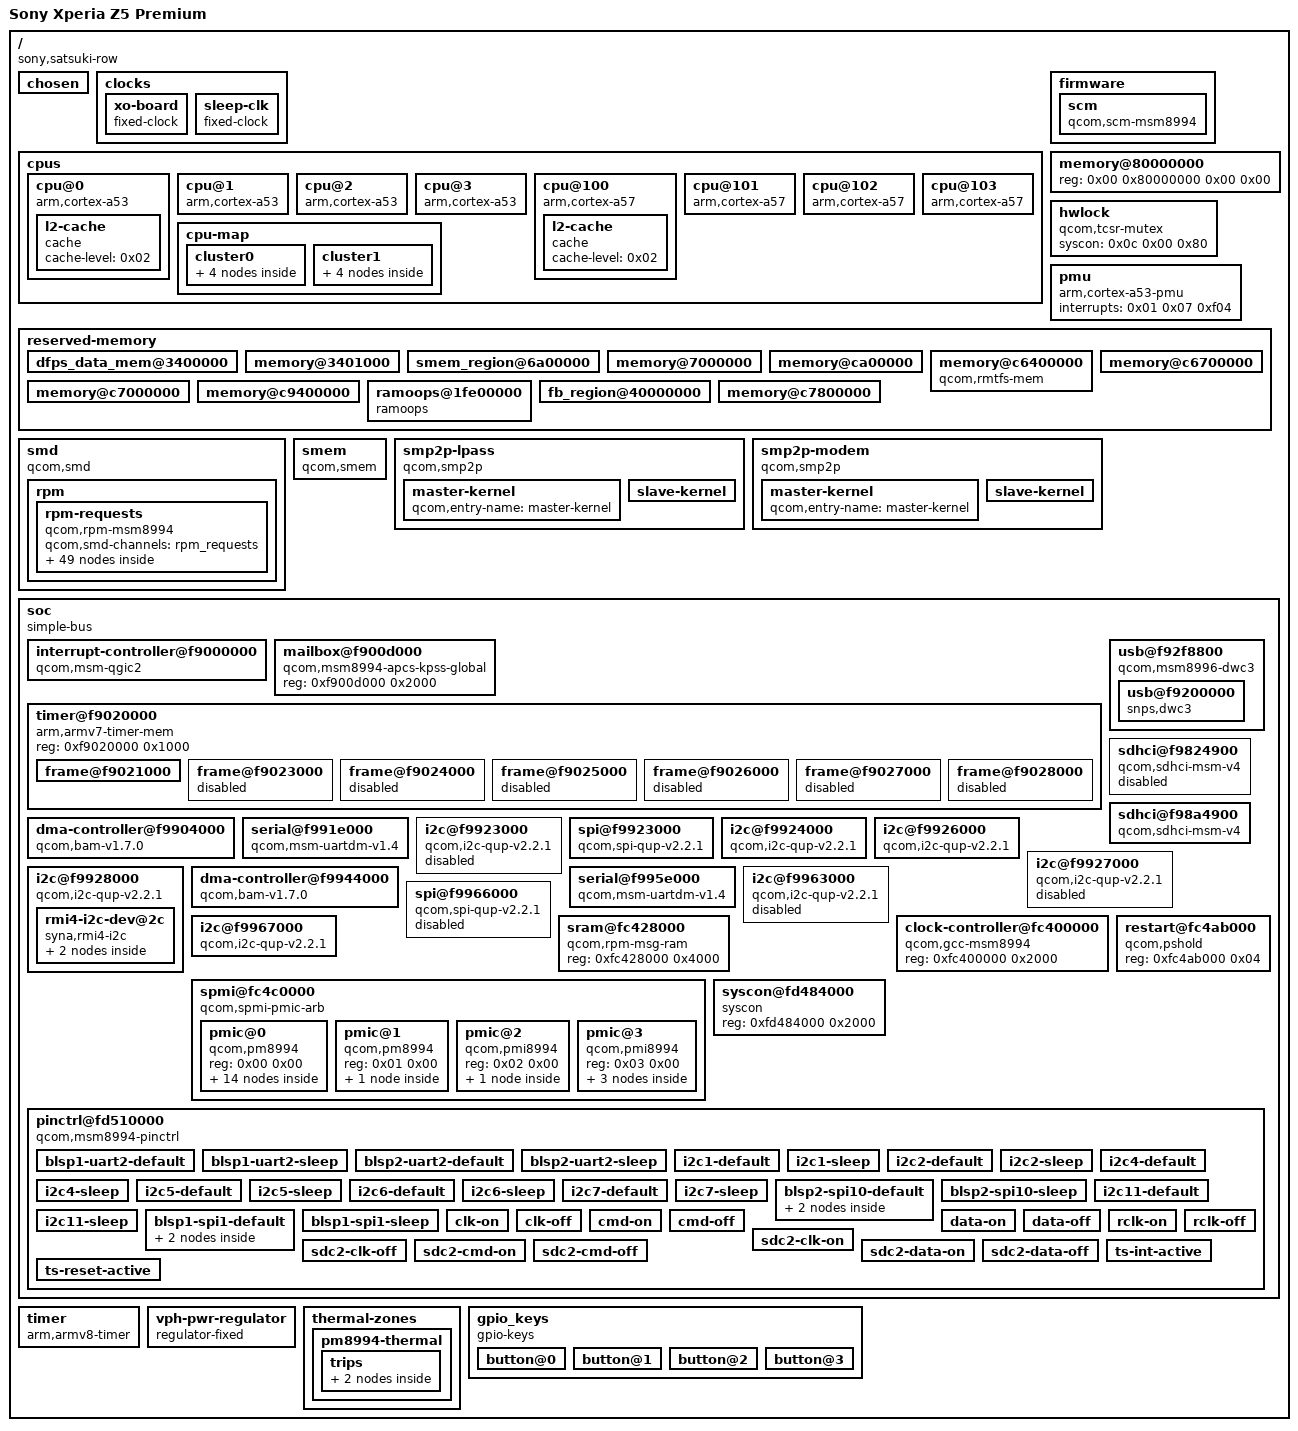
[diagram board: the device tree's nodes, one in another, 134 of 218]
/dts-v1/;

/ {
	interrupt-parent = <0x01>;
	#address-cells = <0x02>;
	#size-cells = <0x02>;
	qcom,msm-id = <0xcf 0x20000 0xcf 0x20001>;
	qcom,pmic-id = <0x10009 0x1000a 0x00 0x00>;
	qcom,board-id = <0x08 0x00>;
	model = "Sony Xperia Z5 Premium";
	compatible = "sony,satsuki-row\0qcom,msm8994";

	chosen {
	};

	clocks {

		xo-board {
			compatible = "fixed-clock";
			#clock-cells = <0x00>;
			clock-frequency = <0x124f800>;
			clock-output-names = "xo_board";
			phandle = <0x19>;
		};

		sleep-clk {
			compatible = "fixed-clock";
			#clock-cells = <0x00>;
			clock-frequency = <0x8000>;
			clock-output-names = "sleep_clk";
			phandle = <0x4a>;
		};
	};

	cpus {
		#address-cells = <0x02>;
		#size-cells = <0x00>;

		cpu@0 {
			device_type = "cpu";
			compatible = "arm,cortex-a53";
			reg = <0x00 0x00>;
			enable-method = "psci";
			next-level-cache = <0x02>;
			phandle = <0x04>;

			l2-cache {
				compatible = "cache";
				cache-level = <0x02>;
				phandle = <0x02>;
			};
		};

		cpu@1 {
			device_type = "cpu";
			compatible = "arm,cortex-a53";
			reg = <0x00 0x01>;
			enable-method = "psci";
			next-level-cache = <0x02>;
			phandle = <0x05>;
		};

		cpu@2 {
			device_type = "cpu";
			compatible = "arm,cortex-a53";
			reg = <0x00 0x02>;
			enable-method = "psci";
			next-level-cache = <0x02>;
			phandle = <0x06>;
		};

		cpu@3 {
			device_type = "cpu";
			compatible = "arm,cortex-a53";
			reg = <0x00 0x03>;
			enable-method = "psci";
			next-level-cache = <0x02>;
			phandle = <0x07>;
		};

		cpu@100 {
			device_type = "cpu";
			compatible = "arm,cortex-a57";
			reg = <0x00 0x100>;
			enable-method = "psci";
			next-level-cache = <0x03>;
			phandle = <0x08>;

			l2-cache {
				compatible = "cache";
				cache-level = <0x02>;
				phandle = <0x03>;
			};
		};

		cpu@101 {
			device_type = "cpu";
			compatible = "arm,cortex-a57";
			reg = <0x00 0x101>;
			enable-method = "psci";
			next-level-cache = <0x03>;
			phandle = <0x09>;
		};

		cpu@102 {
			device_type = "cpu";
			compatible = "arm,cortex-a57";
			reg = <0x00 0x102>;
			enable-method = "psci";
			next-level-cache = <0x03>;
			phandle = <0x0a>;
		};

		cpu@103 {
			device_type = "cpu";
			compatible = "arm,cortex-a57";
			reg = <0x00 0x103>;
			enable-method = "psci";
			next-level-cache = <0x03>;
			phandle = <0x0b>;
		};

		cpu-map {

			cluster0 {

				core0 {
					cpu = <0x04>;
				};

				core1 {
					cpu = <0x05>;
				};

				core2 {
					cpu = <0x06>;
				};

				core3 {
					cpu = <0x07>;
				};
			};

			cluster1 {

				core0 {
					cpu = <0x08>;
				};

				core1 {
					cpu = <0x09>;
				};

				core2 {
					cpu = <0x0a>;
					phandle = <0x4b>;
				};

				core3 {
					cpu = <0x0b>;
					phandle = <0x4c>;
				};
			};
		};
	};

	firmware {

		scm {
			compatible = "qcom,scm-msm8994\0qcom,scm";
		};
	};

	memory@80000000 {
		device_type = "memory";
		reg = <0x00 0x80000000 0x00 0x00>;
	};

	hwlock {
		compatible = "qcom,tcsr-mutex";
		syscon = <0x0c 0x00 0x80>;
		#hwlock-cells = <0x01>;
		phandle = <0x17>;
	};

	pmu {
		compatible = "arm,cortex-a53-pmu";
		interrupts = <0x01 0x07 0xf04>;
	};

	reserved-memory {
		#address-cells = <0x02>;
		#size-cells = <0x02>;
		ranges;

		dfps_data_mem@3400000 {
			reg = <0x00 0x3400000 0x00 0x1000>;
			no-map;
			phandle = <0x4d>;
		};

		memory@3401000 {
			reg = <0x00 0x3401000 0x00 0x2200000>;
			no-map;
			phandle = <0x4e>;
		};

		smem_region@6a00000 {
			reg = <0x00 0x6a00000 0x00 0x200000>;
			no-map;
			phandle = <0x15>;
		};

		memory@7000000 {
			reg = <0x00 0x7000000 0x00 0x5a00000>;
			no-map;
			phandle = <0x4f>;
		};

		memory@ca00000 {
			reg = <0x00 0xca00000 0x00 0x1f00000>;
			no-map;
			phandle = <0x50>;
		};

		memory@c6400000 {
			compatible = "qcom,rmtfs-mem";
			reg = <0x00 0xc6400000 0x00 0x180000>;
			no-map;
			qcom,client-id = <0x01>;
			phandle = <0x51>;
		};

		memory@c6700000 {
			reg = <0x00 0xc6700000 0x00 0x100000>;
			no-map;
			phandle = <0x52>;
		};

		memory@c7000000 {
			reg = <0x00 0xc7000000 0x00 0x800000>;
			no-map;
			phandle = <0x53>;
		};

		memory@c9400000 {
			reg = <0x00 0xc9400000 0x00 0x3f00000>;
			no-map;
			phandle = <0x54>;
		};

		ramoops@1fe00000 {
			compatible = "ramoops";
			reg = <0x00 0x1fe00000 0x00 0x200000>;
			console-size = <0x100000>;
			record-size = <0x10000>;
			ftrace-size = <0x10000>;
			pmsg-size = <0x80000>;
		};

		fb_region@40000000 {
			reg = <0x00 0x40000000 0x00 0x1000000>;
			no-map;
			phandle = <0x55>;
		};

		memory@c7800000 {
			reg = <0x00 0xc7800000 0x00 0x1900000>;
			no-map;
			phandle = <0x56>;
		};
	};

	smd {
		compatible = "qcom,smd";

		rpm {
			interrupts = <0x00 0xa8 0x01>;
			qcom,ipc = <0x0d 0x08 0x00>;
			qcom,smd-edge = <0x0f>;
			qcom,local-pid = <0x00>;
			qcom,remote-pid = <0x06>;

			rpm-requests {
				compatible = "qcom,rpm-msm8994";
				qcom,smd-channels = "rpm_requests";
				phandle = <0x57>;

				rpmcc {
					compatible = "qcom,rpmcc-msm8994";
					#clock-cells = <0x01>;
					phandle = <0x58>;
				};

				power-controller {
					compatible = "qcom,msm8994-rpmpd";
					#power-domain-cells = <0x01>;
					operating-points-v2 = <0x0e>;
					phandle = <0x59>;

					opp-table {
						compatible = "operating-points-v2";
						phandle = <0x0e>;

						opp1 {
							opp-level = <0x01>;
							phandle = <0x5a>;
						};

						opp2 {
							opp-level = <0x02>;
							phandle = <0x5b>;
						};

						opp3 {
							opp-level = <0x03>;
							phandle = <0x5c>;
						};

						opp4 {
							opp-level = <0x04>;
							phandle = <0x5d>;
						};

						opp5 {
							opp-level = <0x05>;
							phandle = <0x5e>;
						};

						opp6 {
							opp-level = <0x06>;
							phandle = <0x5f>;
						};
					};
				};

				pm8994-regulators {
					compatible = "qcom,rpm-pm8994-regulators";
					vdd_s1-supply = <0x0f>;
					vdd_s2-supply = <0x0f>;
					vdd_s3-supply = <0x0f>;
					vdd_s4-supply = <0x0f>;
					vdd_s5-supply = <0x0f>;
					vdd_s6-supply = <0x0f>;
					vdd_s7-supply = <0x0f>;
					vdd_s8-supply = <0x0f>;
					vdd_s9-supply = <0x0f>;
					vdd_s10-supply = <0x0f>;
					vdd_s11-supply = <0x0f>;
					vdd_s12-supply = <0x0f>;
					vdd_l1-supply = <0x10>;
					vdd_l2_l26_l28-supply = <0x11>;
					vdd_l3_l11-supply = <0x11>;
					vdd_l4_l27_l31-supply = <0x11>;
					vdd_l5_l7-supply = <0x12>;
					vdd_l6_l12_l32-supply = <0x12>;
					vdd_l8_l16_l30-supply = <0x0f>;
					vdd_l9_l10_l18_l22-supply = <0x13>;
					vdd_l13_l19_l23_l24-supply = <0x13>;
					vdd_l14_l15-supply = <0x12>;
					vdd_l17_l29-supply = <0x13>;
					vdd_l20_l21-supply = <0x13>;
					vdd_l25-supply = <0x11>;
					vdd_lvs1_lvs2-supply = <0x14>;
					phandle = <0x60>;

					s3 {
						regulator-min-microvolt = <0x13d620>;
						regulator-max-microvolt = <0x13d620>;
						phandle = <0x11>;
					};

					s4 {
						regulator-min-microvolt = <0x1b7740>;
						regulator-max-microvolt = <0x1b7740>;
						regulator-allow-set-load;
						regulator-always-on;
						regulator-system-load = <0x4f588>;
						phandle = <0x14>;
					};

					s5 {
						regulator-min-microvolt = <0x20ce70>;
						regulator-max-microvolt = <0x20ce70>;
						phandle = <0x12>;
					};

					s7 {
						regulator-min-microvolt = <0xf4240>;
						regulator-max-microvolt = <0xf4240>;
						phandle = <0x61>;
					};

					l1 {
						regulator-min-microvolt = <0xf4240>;
						regulator-max-microvolt = <0xf4240>;
						phandle = <0x62>;
					};

					l2 {
						regulator-min-microvolt = <0x1312d0>;
						regulator-max-microvolt = <0x1312d0>;
						regulator-allow-set-load;
						regulator-system-load = <0x2710>;
						phandle = <0x63>;
					};

					l3 {
						regulator-min-microvolt = <0x10c8e0>;
						regulator-max-microvolt = <0x10c8e0>;
						phandle = <0x64>;
					};

					l4 {
						regulator-min-microvolt = <0x12b128>;
						regulator-max-microvolt = <0x12b128>;
						phandle = <0x65>;
					};

					l6 {
						regulator-min-microvolt = <0x1b7740>;
						regulator-max-microvolt = <0x1b7740>;
						phandle = <0x66>;
					};

					l8 {
						regulator-min-microvolt = <0x1b7740>;
						regulator-max-microvolt = <0x1b7740>;
						phandle = <0x67>;
					};

					l9 {
						regulator-min-microvolt = <0x1b7740>;
						regulator-max-microvolt = <0x1b7740>;
						phandle = <0x68>;
					};

					l10 {
						regulator-min-microvolt = <0x1b7740>;
						regulator-max-microvolt = <0x1b7740>;
						phandle = <0x69>;
					};

					l11 {
						regulator-min-microvolt = <0x124f80>;
						regulator-max-microvolt = <0x124f80>;
						phandle = <0x6a>;
					};

					l12 {
						regulator-min-microvolt = <0x1b7740>;
						regulator-max-microvolt = <0x1b7740>;
						regulator-allow-set-load;
						regulator-system-load = <0x2710>;
						phandle = <0x6b>;
					};

					l13 {
						regulator-min-microvolt = <0x1b7740>;
						regulator-max-microvolt = <0x2d0370>;
						phandle = <0x2a>;
					};

					l14 {
						regulator-min-microvolt = <0x1c3a90>;
						regulator-max-microvolt = <0x1c3a90>;
						regulator-allow-set-load;
						regulator-system-load = <0x2710>;
						phandle = <0x6c>;
					};

					l15 {
						regulator-min-microvolt = <0x1b7740>;
						regulator-max-microvolt = <0x1b7740>;
						phandle = <0x6d>;
					};

					l16 {
						regulator-min-microvolt = <0x2932e0>;
						regulator-max-microvolt = <0x2932e0>;
						phandle = <0x6e>;
					};

					l17 {
						regulator-min-microvolt = <0x2191c0>;
						regulator-max-microvolt = <0x2191c0>;
						phandle = <0x6f>;
					};

					l18 {
						regulator-min-microvolt = <0x2b7cd0>;
						regulator-max-microvolt = <0x2b7cd0>;
						regulator-always-on;
						phandle = <0x70>;
					};

					l19 {
						regulator-min-microvolt = <0x2b7cd0>;
						regulator-max-microvolt = <0x2b7cd0>;
						phandle = <0x71>;
					};

					l20 {
						regulator-min-microvolt = <0x2d0370>;
						regulator-max-microvolt = <0x2d0370>;
						regulator-always-on;
						regulator-boot-on;
						regulator-allow-set-load;
						regulator-system-load = <0x8b290>;
						phandle = <0x72>;
					};

					l21 {
						regulator-min-microvolt = <0x2d0370>;
						regulator-max-microvolt = <0x2d0370>;
						regulator-always-on;
						regulator-allow-set-load;
						regulator-system-load = "\0\f5";
						phandle = <0x29>;
					};

					l22 {
						regulator-min-microvolt = <0x2dc6c0>;
						regulator-max-microvolt = <0x2dc6c0>;
						phandle = <0x3d>;
					};

					l23 {
						regulator-min-microvolt = <0x2ab980>;
						regulator-max-microvolt = <0x2ab980>;
						phandle = <0x73>;
					};

					l24 {
						regulator-min-microvolt = <0x2eebb8>;
						regulator-max-microvolt = <0x3010b0>;
						phandle = <0x74>;
					};

					l25 {
						regulator-min-microvolt = <0xf4240>;
						regulator-max-microvolt = <0xf4240>;
						phandle = <0x75>;
					};

					l26 {
						regulator-min-microvolt = <0xf116c>;
						regulator-max-microvolt = <0xf116c>;
						phandle = <0x76>;
					};

					l27 {
						regulator-min-microvolt = <0x124f80>;
						regulator-max-microvolt = <0x124f80>;
						phandle = <0x77>;
					};

					l28 {
						regulator-min-microvolt = <0xf4240>;
						regulator-max-microvolt = <0xf4240>;
						regulator-allow-set-load;
						regulator-system-load = <0x2710>;
						phandle = <0x78>;
					};

					l29 {
						regulator-min-microvolt = <0x2932e0>;
						regulator-max-microvolt = <0x2932e0>;
						phandle = <0x79>;
					};

					l30 {
						regulator-min-microvolt = <0x1b7740>;
						regulator-max-microvolt = <0x1b7740>;
						phandle = <0x7a>;
					};

					l31 {
						regulator-min-microvolt = <0x124f80>;
						regulator-max-microvolt = <0x124f80>;
						regulator-allow-set-load;
						regulator-system-load = <0x2710>;
						phandle = <0x7b>;
					};

					l32 {
						regulator-min-microvolt = <0x1b7740>;
						regulator-max-microvolt = <0x1b7740>;
						phandle = <0x7c>;
					};

					lvs1 {
						phandle = <0x7d>;
					};

					lvs2 {
						phandle = <0x7e>;
					};
				};

				pmi8994-regulators {
					compatible = "qcom,rpm-pmi8994-regulators";
					vdd_s1-supply = <0x0f>;
					vdd_bst_byp-supply = <0x0f>;
					phandle = <0x7f>;

					s1 {
						regulator-min-microvolt = <0xfa3e8>;
						regulator-max-microvolt = <0xfa3e8>;
						phandle = <0x10>;
					};

					boost-bypass {
						regulator-min-microvolt = <0x3010b0>;
						regulator-max-microvolt = <0x36ee80>;
						phandle = <0x13>;
					};
				};
			};
		};
	};

	smem {
		compatible = "qcom,smem";
		memory-region = <0x15>;
		qcom,rpm-msg-ram = <0x16>;
		hwlocks = <0x17 0x03>;
	};

	smp2p-lpass {
		compatible = "qcom,smp2p";
		qcom,smem = <0x1bb 0x1ad>;
		interrupts = <0x00 0x9e 0x01>;
		qcom,ipc = <0x0d 0x08 0x0a>;
		qcom,local-pid = <0x00>;
		qcom,remote-pid = <0x02>;

		master-kernel {
			qcom,entry-name = "master-kernel";
			#qcom,smem-state-cells = <0x01>;
			phandle = <0x80>;
		};

		slave-kernel {
			qcom,entry-name = "slave-kernel";
			interrupt-controller;
			#interrupt-cells = <0x02>;
			phandle = <0x81>;
		};
	};

	smp2p-modem {
		compatible = "qcom,smp2p";
		qcom,smem = <0x1b3 0x1ac>;
		interrupt-parent = <0x01>;
		interrupts = <0x00 0x1b 0x01>;
		qcom,ipc = <0x0d 0x08 0x0e>;
		qcom,local-pid = <0x00>;
		qcom,remote-pid = <0x01>;

		master-kernel {
			qcom,entry-name = "master-kernel";
			#qcom,smem-state-cells = <0x01>;
			phandle = <0x82>;
		};

		slave-kernel {
			qcom,entry-name = "slave-kernel";
			interrupt-controller;
			#interrupt-cells = <0x02>;
			phandle = <0x83>;
		};
	};

	soc {
		#address-cells = <0x01>;
		#size-cells = <0x01>;
		ranges = <0x00 0x00 0x00 0xffffffff>;
		compatible = "simple-bus";
		phandle = <0x84>;

		interrupt-controller@f9000000 {
			compatible = "qcom,msm-qgic2";
			interrupt-controller;
			#interrupt-cells = <0x03>;
			reg = <0xf9000000 0x1000 0xf9002000 0x1000>;
			phandle = <0x01>;
		};

		mailbox@f900d000 {
			compatible = "qcom,msm8994-apcs-kpss-global\0syscon";
			reg = <0xf900d000 0x2000>;
			#mbox-cells = <0x01>;
			phandle = <0x0d>;
		};

		timer@f9020000 {
			#address-cells = <0x01>;
			#size-cells = <0x01>;
			ranges;
			compatible = "arm,armv7-timer-mem";
			reg = <0xf9020000 0x1000>;

			frame@f9021000 {
				frame-number = <0x00>;
				interrupts = <0x00 0x09 0x04 0x00 0x08 0x04>;
				reg = <0xf9021000 0x1000 0xf9022000 0x1000>;
			};

			frame@f9023000 {
				frame-number = <0x01>;
				interrupts = <0x00 0x0a 0x04>;
				reg = <0xf9023000 0x1000>;
				status = "disabled";
			};

			frame@f9024000 {
				frame-number = <0x02>;
				interrupts = <0x00 0x0b 0x04>;
				reg = <0xf9024000 0x1000>;
				status = "disabled";
			};

			frame@f9025000 {
				frame-number = <0x03>;
				interrupts = <0x00 0x0c 0x04>;
				reg = <0xf9025000 0x1000>;
				status = "disabled";
			};

			frame@f9026000 {
				frame-number = <0x04>;
				interrupts = <0x00 0x0d 0x04>;
				reg = <0xf9026000 0x1000>;
				status = "disabled";
			};

			frame@f9027000 {
				frame-number = <0x05>;
				interrupts = <0x00 0x0e 0x04>;
				reg = <0xf9027000 0x1000>;
				status = "disabled";
			};

			frame@f9028000 {
				frame-number = <0x06>;
				interrupts = <0x00 0x0f 0x04>;
				reg = <0xf9028000 0x1000>;
				status = "disabled";
			};
		};

		usb@f92f8800 {
			compatible = "qcom,msm8996-dwc3\0qcom,dwc3";
			reg = <0xf92f8800 0x400>;
			#address-cells = <0x01>;
			#size-cells = <0x01>;
			ranges;
			clocks = <0x18 0x72 0x18 0x6d 0x18 0x8a 0x18 0x73>;
			clock-names = "core\0iface\0sleep\0mock_utmi\0ref\0xo";
			assigned-clocks = <0x18 0x73 0x18 0x72>;
			assigned-clock-rates = <0x124f800 0x7270e00>;
			power-domains = <0x18 0x03>;
			qcom,select-utmi-as-pipe-clk;
			phandle = <0x85>;

			usb@f9200000 {
				compatible = "snps,dwc3";
				reg = <0xf9200000 0xcc00>;
				interrupts = <0x00 0x83 0x04>;
				snps,dis_u2_susphy_quirk;
				snps,dis_enblslpm_quirk;
				maximum-speed = "high-speed";
				dr_mode = "peripheral";
			};
		};

		sdhci@f9824900 {
			compatible = "qcom,sdhci-msm-v4";
			reg = <0xf9824900 0x1a0 0xf9824000 0x800>;
			reg-names = "hc_mem\0core_mem";
			interrupts = <0x00 0x7b 0x04 0x00 0x8a 0x04>;
			interrupt-names = "hc_irq\0pwr_irq";
			clocks = <0x18 0x68 0x18 0x76 0x19>;
			clock-names = "core\0iface\0xo";
			pinctrl-names = "default\0sleep";
			pinctrl-0 = <0x1a 0x1b 0x1c 0x1d>;
			pinctrl-1 = <0x1e 0x1f 0x20 0x21>;
			bus-width = <0x08>;
			non-removable;
			status = "disabled";
			phandle = <0x86>;
		};

		sdhci@f98a4900 {
			compatible = "qcom,sdhci-msm-v4";
			reg = <0xf98a4900 0x11c 0xf98a4000 0x800>;
			reg-names = "hc_mem\0core_mem";
			interrupts = <0x00 0x7d 0x04 0x00 0xdd 0x04>;
			interrupt-names = "hc_irq\0pwr_irq";
			clocks = <0x18 0x69 0x18 0x80 0x19>;
			clock-names = "core\0iface\0xo";
			pinctrl-names = "default\0sleep";
			pinctrl-0 = <0x22 0x23 0x24>;
			pinctrl-1 = <0x25 0x26 0x27>;
			cd-gpios = <0x28 0x64 0x00>;
			bus-width = <0x04>;
			status = "okay";
			vmmc-supply = <0x29>;
			vqmmc-supply = <0x2a>;
			phandle = <0x87>;
		};

		dma-controller@f9904000 {
			compatible = "qcom,bam-v1.7.0";
			reg = <0xf9904000 0x19000>;
			interrupts = <0x00 0xee 0x04>;
			clocks = <0x18 0x3a>;
			clock-names = "bam_clk";
			#dma-cells = <0x01>;
			qcom,ee = <0x00>;
			qcom,controlled-remotely;
			num-channels = <0x18>;
			qcom,num-ees = <0x04>;
			phandle = <0x2d>;
		};

		serial@f991e000 {
			compatible = "qcom,msm-uartdm-v1.4\0qcom,msm-uartdm";
			reg = <0xf991e000 0x1000>;
			interrupts = <0x00 0x6c 0x04>;
			clock-names = "core\0iface";
			clocks = <0x18 0x48 0x18 0x3a>;
			pinctrl-names = "default\0sleep";
			pinctrl-0 = <0x2b>;
			pinctrl-1 = <0x2c>;
			status = "okay";
			phandle = <0x88>;
		};

		i2c@f9923000 {
			compatible = "qcom,i2c-qup-v2.2.1";
			reg = <0xf9923000 0x500>;
			interrupts = <0x00 0x5f 0x04>;
			clocks = <0x18 0x3a 0x18 0x3b>;
			clock-names = "iface\0core";
			clock-frequency = <0x61a80>;
			dmas = <0x2d 0x0c 0x2d 0x0d>;
			dma-names = "tx\0rx";
			pinctrl-names = "default\0sleep";
			pinctrl-0 = <0x2e>;
			pinctrl-1 = <0x2f>;
			#address-cells = <0x01>;
			#size-cells = <0x00>;
			status = "disabled";
			phandle = <0x89>;
		};

		spi@f9923000 {
			compatible = "qcom,spi-qup-v2.2.1";
			reg = <0xf9923000 0x500>;
			interrupts = <0x00 0x5f 0x04>;
			clocks = <0x18 0x3c 0x18 0x3a>;
			clock-names = "core\0iface";
			spi-max-frequency = <0x124f800>;
			dmas = <0x2d 0x0c 0x2d 0x0d>;
			dma-names = "tx\0rx";
			pinctrl-names = "default\0sleep";
			pinctrl-0 = <0x30>;
			pinctrl-1 = <0x31>;
			#address-cells = <0x01>;
			#size-cells = <0x00>;
			status = "okay";
			phandle = <0x8a>;
		};

		i2c@f9924000 {
			compatible = "qcom,i2c-qup-v2.2.1";
			reg = <0xf9924000 0x500>;
			interrupts = <0x00 0x60 0x04>;
			clocks = <0x18 0x3a 0x18 0x3d>;
			clock-names = "iface\0core";
			clock-frequency = <0x56ab8>;
			dmas = <0x2d 0x0e 0x2d 0x0f>;
			dma-names = "tx\0rx";
			pinctrl-names = "default\0sleep";
			pinctrl-0 = <0x32>;
			pinctrl-1 = <0x33>;
			#address-cells = <0x01>;
			#size-cells = <0x00>;
			status = "okay";
			phandle = <0x8b>;
		};

		i2c@f9926000 {
			compatible = "qcom,i2c-qup-v2.2.1";
			reg = <0xf9926000 0x500>;
			interrupts = <0x00 0x62 0x04>;
			clocks = <0x18 0x3a 0x18 0x41>;
			clock-names = "iface\0core";
			clock-frequency = <0x56ab8>;
			dmas = <0x2d 0x12 0x2d 0x13>;
			dma-names = "tx\0rx";
			pinctrl-names = "default\0sleep";
			pinctrl-0 = <0x34>;
			pinctrl-1 = <0x35>;
			#address-cells = <0x01>;
			#size-cells = <0x00>;
			status = "okay";
			phandle = <0x8c>;
		};

		i2c@f9927000 {
			compatible = "qcom,i2c-qup-v2.2.1";
			reg = <0xf9927000 0x500>;
			interrupts = <0x00 0x63 0x04>;
			clocks = <0x18 0x3a 0x18 0x43>;
			clock-names = "iface\0core";
			clock-frequency = <0x61a80>;
			dmas = <0x36 0x14 0x36 0x15>;
			dma-names = "tx\0rx";
			pinctrl-names = "default\0sleep";
			pinctrl-0 = <0x37>;
			pinctrl-1 = <0x38>;
			#address-cells = <0x01>;
			#size-cells = <0x00>;
			status = "disabled";
			phandle = <0x8d>;
		};

		i2c@f9928000 {
			compatible = "qcom,i2c-qup-v2.2.1";
			reg = <0xf9928000 0x500>;
			interrupts = <0x00 0x64 0x04>;
			clocks = <0x18 0x3a 0x18 0x45>;
			clock-names = "iface\0core";
			clock-frequency = <0x56ab8>;
			dmas = <0x2d 0x16 0x2d 0x17>;
			dma-names = "tx\0rx";
			pinctrl-names = "default\0sleep";
			pinctrl-0 = <0x39>;
			pinctrl-1 = <0x3a>;
			#address-cells = <0x01>;
			#size-cells = <0x00>;
			status = "okay";
			phandle = <0x8e>;

			rmi4-i2c-dev@2c {
				compatible = "syna,rmi4-i2c";
				reg = <0x2c>;
				#address-cells = <0x01>;
				#size-cells = <0x00>;
				interrupt-parent = <0x28>;
				interrupts = <0x2a 0x02>;
				pinctrl-names = "default";
				pinctrl-0 = <0x3b 0x3c>;
				vdd-supply = <0x3d>;
				vio-supply = <0x14>;
				syna,reset-delay-ms = <0xdc>;
				syna,startup-delay-ms = <0xdc>;
				phandle = <0x8f>;

				rmi4-f01@1 {
					reg = <0x01>;
					syna,nosleep-mode = <0x01>;
				};

				rmi4-f11@11 {
					reg = <0x11>;
					syna,sensor-type = <0x01>;
				};
			};
		};

		dma-controller@f9944000 {
			compatible = "qcom,bam-v1.7.0";
			reg = <0xf9944000 0x19000>;
			interrupts = <0x00 0xef 0x04>;
			clocks = <0x18 0x4d>;
			clock-names = "bam_clk";
			#dma-cells = <0x01>;
			qcom,ee = <0x00>;
			qcom,controlled-remotely;
			num-channels = <0x18>;
			qcom,num-ees = <0x04>;
			phandle = <0x36>;
		};

		serial@f995e000 {
			compatible = "qcom,msm-uartdm-v1.4\0qcom,msm-uartdm";
			reg = <0xf995e000 0x1000>;
			interrupts = <0x00 0x72 0x04>;
			clock-names = "core\0iface";
			clocks = <0x18 0x5b 0x18 0x4d>;
			dmas = <0x36 0x02 0x36 0x03>;
			dma-names = "tx\0rx";
			pinctrl-names = "default\0sleep";
			pinctrl-0 = <0x3e>;
			pinctrl-1 = <0x3f>;
			status = "okay";
			phandle = <0x90>;
		};

		i2c@f9963000 {
			compatible = "qcom,i2c-qup-v2.2.1";
			reg = <0xf9963000 0x500>;
			interrupts = <0x00 0x65 0x04>;
			clocks = <0x18 0x4d 0x18 0x4e>;
			clock-names = "iface\0core";
			clock-frequency = <0x61a80>;
			dmas = <0x36 0x0c 0x36 0x0d>;
			dma-names = "tx\0rx";
			pinctrl-names = "default\0sleep";
			pinctrl-0 = <0x40>;
			pinctrl-1 = <0x41>;
			#address-cells = <0x01>;
			#size-cells = <0x00>;
			status = "disabled";
			phandle = <0x91>;
		};

		spi@f9966000 {
			compatible = "qcom,spi-qup-v2.2.1";
			reg = <0xf9966000 0x500>;
			interrupts = <0x00 0x68 0x04>;
			clocks = <0x18 0x55 0x18 0x4d>;
			clock-names = "core\0iface";
			spi-max-frequency = <0x124f800>;
			dmas = <0x36 0x12 0x36 0x13>;
			dma-names = "tx\0rx";
			pinctrl-names = "default\0sleep";
			pinctrl-0 = <0x42>;
			pinctrl-1 = <0x43>;
			#address-cells = <0x01>;
			#size-cells = <0x00>;
			status = "disabled";
			phandle = <0x92>;
		};

		i2c@f9967000 {
			compatible = "qcom,i2c-qup-v2.2.1";
			reg = <0xf9967000 0x500>;
			interrupts = <0x00 0x69 0x04>;
			clocks = <0x18 0x4d 0x18 0x56>;
			clock-names = "iface\0core";
			clock-frequency = <0x56ab8>;
			dmas = <0x36 0x14 0x36 0x15>;
			dma-names = "tx\0rx";
			pinctrl-names = "default\0sleep";
			pinctrl-0 = <0x44>;
			pinctrl-1 = <0x45>;
			#address-cells = <0x01>;
			#size-cells = <0x00>;
			status = "okay";
			phandle = <0x93>;
		};

		clock-controller@fc400000 {
			compatible = "qcom,gcc-msm8994";
			#clock-cells = <0x01>;
			#reset-cells = <0x01>;
			#power-domain-cells = <0x01>;
			reg = <0xfc400000 0x2000>;
			phandle = <0x18>;
		};

		sram@fc428000 {
			compatible = "qcom,rpm-msg-ram";
			reg = <0xfc428000 0x4000>;
			phandle = <0x16>;
		};

		restart@fc4ab000 {
			compatible = "qcom,pshold";
			reg = <0xfc4ab000 0x04>;
		};

		spmi@fc4c0000 {
			compatible = "qcom,spmi-pmic-arb";
			reg = <0xfc4cf000 0x1000 0xfc4cb000 0x1000 0xfc4ca000 0x1000>;
			reg-names = "core\0intr\0cnfg";
			interrupt-names = "periph_irq";
			interrupts = <0x00 0xbe 0x04>;
			qcom,ee = <0x00>;
			qcom,channel = <0x00>;
			#address-cells = <0x02>;
			#size-cells = <0x00>;
			interrupt-controller;
			#interrupt-cells = <0x04>;
			phandle = <0x94>;

			pmic@0 {
				compatible = "qcom,pm8994\0qcom,spmi-pmic";
				reg = <0x00 0x00>;
				#address-cells = <0x01>;
				#size-cells = <0x00>;

				rtc@6000 {
					compatible = "qcom,pm8941-rtc";
					reg = <0x6000 0x6100>;
					reg-names = "rtc\0alarm";
					interrupts = <0x00 0x61 0x01 0x01>;
				};

				pon@800 {
					compatible = "qcom,pm8916-pon";
					reg = <0x800>;
					mode-bootloader = <0x02>;
					mode-recovery = <0x01>;
					phandle = <0x95>;

					pwrkey {
						compatible = "qcom,pm8941-pwrkey";
						interrupts = <0x00 0x08 0x00 0x03>;
						debounce = <0x3d09>;
						bias-pull-up;
						linux,code = <0x74>;
					};

					resin {
						compatible = "qcom,pm8941-resin";
						interrupts = <0x00 0x08 0x01 0x03>;
						debounce = <0x3d09>;
						bias-pull-up;
						status = "disabled";
						phandle = <0x96>;
					};
				};

				temp-alarm@2400 {
					compatible = "qcom,spmi-temp-alarm";
					reg = <0x2400>;
					interrupts = <0x00 0x24 0x00 0x01>;
					io-channels = <0x46 0x08>;
					io-channel-names = "thermal";
					#thermal-sensor-cells = <0x00>;
					phandle = <0x49>;
				};

				adc@3100 {
					compatible = "qcom,spmi-vadc";
					reg = <0x3100>;
					interrupts = <0x00 0x31 0x00 0x01>;
					#address-cells = <0x01>;
					#size-cells = <0x00>;
					#io-channel-cells = <0x01>;
					phandle = <0x46>;

					adc-chan@7 {
						reg = <0x07>;
						qcom,pre-scaling = <0x01 0x03>;
						label = "vph_pwr";
					};

					adc-chan@8 {
						reg = <0x08>;
						label = "die_temp";
					};

					adc-chan@9 {
						reg = <0x09>;
						label = "ref_625mv";
					};

					adc-chan@a {
						reg = <0x0a>;
						label = "ref_1250mv";
					};

					adc-chan@e {
						reg = <0x0e>;
					};

					adc-chan@f {
						reg = <0x0f>;
					};
				};

				gpios@c000 {
					compatible = "qcom,pm8994-gpio\0qcom,spmi-gpio";
					reg = <0xc000>;
					gpio-controller;
					gpio-ranges = <0x47 0x00 0x00 0x16>;
					#gpio-cells = <0x02>;
					interrupt-controller;
					#interrupt-cells = <0x02>;
					phandle = <0x47>;
				};

				mpps@a000 {
					compatible = "qcom,pm8994-mpp";
					reg = <0xa000>;
					gpio-controller;
					#gpio-cells = <0x02>;
					interrupts = <0x00 0xa0 0x00 0x00 0x00 0xa1 0x00 0x00 0x00 0xa2 0x00 0x00 0x00 0xa3 0x00 0x00 0x00 0xa4 0x00 0x00 0x00 0xa5 0x00 0x00 0x00 0xa6 0x00 0x00 0x00 0xa7 0x00 0x00>;
					phandle = <0x97>;
				};
			};

			pmic@1 {
				compatible = "qcom,pm8994\0qcom,spmi-pmic";
				reg = <0x01 0x00>;
				#address-cells = <0x01>;
				#size-cells = <0x00>;

				regulators {
					compatible = "qcom,pm8994-regulators";
					phandle = <0x98>;
				};
			};

			pmic@2 {
				compatible = "qcom,pmi8994\0qcom,spmi-pmic";
				reg = <0x02 0x00>;
				#address-cells = <0x01>;
				#size-cells = <0x00>;

				gpios@c000 {
					compatible = "qcom,pmi8994-gpio\0qcom,spmi-gpio";
					reg = <0xc000>;
					gpio-controller;
					gpio-ranges = <0x48 0x00 0x00 0x0a>;
					#gpio-cells = <0x02>;
					interrupt-controller;
					#interrupt-cells = <0x02>;
					phandle = <0x48>;
				};
			};

			pmic@3 {
				compatible = "qcom,pmi8994\0qcom,spmi-pmic";
				reg = <0x03 0x00>;
				#address-cells = <0x01>;
				#size-cells = <0x00>;

				regulators {
					compatible = "qcom,pmi8994-regulators";
					#address-cells = <0x01>;
					#size-cells = <0x01>;
					phandle = <0x99>;

					s2@1700 {
						reg = <0x1700 0x100>;
						regulator-name = "VDD_GFX";
						regulator-min-microvolt = <0xef420>;
						regulator-max-microvolt = <0xef420>;
						regulator-always-on;
						phandle = <0x9a>;
					};
				};

				wled@d800 {
					compatible = "qcom,pmi8994-wled";
					reg = <0xd800 0xd900>;
					interrupts = <0x03 0xd8 0x02 0x01>;
					interrupt-names = "short";
					qcom,num-strings = <0x03>;
					qcom,enabled-strings = <0x00 0x01 0x02 0x03>;
					qcom,cabc;
					qcom,external-pfet;
					status = "disabled";
					phandle = <0x9b>;
				};
			};
		};

		syscon@fd484000 {
			compatible = "syscon";
			reg = <0xfd484000 0x2000>;
			phandle = <0x0c>;
		};

		pinctrl@fd510000 {
			compatible = "qcom,msm8994-pinctrl";
			reg = <0xfd510000 0x4000>;
			interrupts = <0x00 0xd0 0x04>;
			gpio-controller;
			gpio-ranges = <0x28 0x00 0x00 0x92>;
			#gpio-cells = <0x02>;
			interrupt-controller;
			#interrupt-cells = <0x02>;
			phandle = <0x28>;

			blsp1-uart2-default {
				function = "blsp_uart2";
				pins = "gpio4\0gpio5";
				drive-strength = <0x10>;
				bias-disable;
				phandle = <0x2b>;
			};

			blsp1-uart2-sleep {
				function = "gpio";
				pins = "gpio4\0gpio5";
				drive-strength = <0x02>;
				bias-pull-down;
				phandle = <0x2c>;
			};

			blsp2-uart2-default {
				function = "blsp_uart8";
				pins = "gpio45\0gpio46\0gpio47\0gpio48";
				drive-strength = <0x10>;
				bias-disable;
				phandle = <0x3e>;
			};

			blsp2-uart2-sleep {
				function = "gpio";
				pins = "gpio45\0gpio46\0gpio47\0gpio48";
				drive-strength = <0x02>;
				bias-disable;
				phandle = <0x3f>;
			};

			i2c1-default {
				function = "blsp_i2c1";
				pins = "gpio2\0gpio3";
				drive-strength = <0x02>;
				bias-disable;
				phandle = <0x2e>;
			};

			i2c1-sleep {
				function = "gpio";
				pins = "gpio2\0gpio3";
				drive-strength = <0x02>;
				bias-disable;
				phandle = <0x2f>;
			};

			i2c2-default {
				function = "blsp_i2c2";
				pins = "gpio6\0gpio7";
				drive-strength = <0x02>;
				bias-disable;
				phandle = <0x32>;
			};

			i2c2-sleep {
				function = "gpio";
				pins = "gpio6\0gpio7";
				drive-strength = <0x02>;
				bias-disable;
				phandle = <0x33>;
			};

			i2c4-default {
				function = "blsp_i2c4";
				pins = "gpio19\0gpio20";
				drive-strength = <0x02>;
				bias-disable;
				phandle = <0x34>;
			};

			i2c4-sleep {
				function = "gpio";
				pins = "gpio19\0gpio20";
				drive-strength = <0x02>;
				bias-pull-down;
				input-enable;
				phandle = <0x35>;
			};

			i2c5-default {
				function = "blsp_i2c5";
				pins = "gpio23\0gpio24";
				drive-strength = <0x02>;
				bias-disable;
				phandle = <0x37>;
			};

			i2c5-sleep {
				function = "gpio";
				pins = "gpio23\0gpio24";
				drive-strength = <0x02>;
				bias-disable;
				phandle = <0x38>;
			};

			i2c6-default {
				function = "blsp_i2c6";
				pins = "gpio28\0gpio27";
				drive-strength = <0x02>;
				bias-disable;
				phandle = <0x39>;
			};

			i2c6-sleep {
				function = "gpio";
				pins = "gpio28\0gpio27";
				drive-strength = <0x02>;
				bias-disable;
				phandle = <0x3a>;
			};

			i2c7-default {
				function = "blsp_i2c7";
				pins = "gpio44\0gpio43";
				drive-strength = <0x02>;
				bias-disable;
				phandle = <0x40>;
			};

			i2c7-sleep {
				function = "gpio";
				pins = "gpio44\0gpio43";
				drive-strength = <0x02>;
				bias-disable;
				phandle = <0x41>;
			};

			blsp2-spi10-default {
				phandle = <0x42>;

				default {
					function = "blsp_spi10";
					pins = "gpio53\0gpio54\0gpio55";
					drive-strength = <0x0a>;
					bias-pull-down;
				};

				cs {
					function = "gpio";
					pins = "gpio55";
					drive-strength = <0x02>;
					bias-disable;
				};
			};

			blsp2-spi10-sleep {
				pins = "gpio53\0gpio54\0gpio55";
				drive-strength = <0x02>;
				bias-disable;
				phandle = <0x43>;
			};

			i2c11-default {
				function = "blsp_i2c11";
				pins = "gpio83\0gpio84";
				drive-strength = <0x02>;
				bias-disable;
				phandle = <0x44>;
			};

			i2c11-sleep {
				function = "gpio";
				pins = "gpio83\0gpio84";
				drive-strength = <0x02>;
				bias-disable;
				phandle = <0x45>;
			};

			blsp1-spi1-default {
				phandle = <0x30>;

				default {
					function = "blsp_spi1";
					pins = "gpio0\0gpio1\0gpio3";
					drive-strength = <0x0a>;
					bias-pull-down;
				};

				cs {
					function = "gpio";
					pins = "gpio8";
					drive-strength = <0x02>;
					bias-disable;
				};
			};

			blsp1-spi1-sleep {
				pins = "gpio0\0gpio1\0gpio3";
				drive-strength = <0x02>;
				bias-disable;
				phandle = <0x31>;
			};

			clk-on {
				pins = "sdc1_clk";
				bias-disable;
				drive-strength = <0x10>;
				phandle = <0x1a>;
			};

			clk-off {
				pins = "sdc1_clk";
				bias-disable;
				drive-strength = <0x02>;
				phandle = <0x1e>;
			};

			cmd-on {
				pins = "sdc1_cmd";
				bias-pull-up;
				drive-strength = <0x08>;
				phandle = <0x1b>;
			};

			cmd-off {
				pins = "sdc1_cmd";
				bias-pull-up;
				drive-strength = <0x02>;
				phandle = <0x1f>;
			};

			data-on {
				pins = "sdc1_data";
				bias-pull-up;
				drive-strength = <0x08>;
				phandle = <0x1c>;
			};

			data-off {
				pins = "sdc1_data";
				bias-pull-up;
				drive-strength = <0x02>;
				phandle = <0x20>;
			};

			rclk-on {
				pins = "sdc1_rclk";
				bias-pull-down;
				phandle = <0x1d>;
			};

			rclk-off {
				pins = "sdc1_rclk";
				bias-pull-down;
				phandle = <0x21>;
			};

			sdc2-clk-on {
				pins = "sdc2_clk";
				bias-disable;
				drive-strength = <0x0a>;
				phandle = <0x22>;
			};

			sdc2-clk-off {
				pins = "sdc2_clk";
				bias-disable;
				drive-strength = <0x02>;
				phandle = <0x25>;
			};

			sdc2-cmd-on {
				pins = "sdc2_cmd";
				bias-pull-up;
				drive-strength = <0x0a>;
				phandle = <0x23>;
			};

			sdc2-cmd-off {
				pins = "sdc2_cmd";
				bias-pull-up;
				drive-strength = <0x02>;
				phandle = <0x26>;
			};

			sdc2-data-on {
				pins = "sdc2_data";
				bias-pull-up;
				drive-strength = <0x0a>;
				phandle = <0x24>;
			};

			sdc2-data-off {
				pins = "sdc2_data";
				bias-pull-up;
				drive-strength = <0x02>;
				phandle = <0x27>;
			};

			ts-int-active {
				pins = "gpio42";
				drive-strength = <0x02>;
				bias-disable;
				input-enable;
				phandle = <0x3b>;
			};

			ts-reset-active {
				pins = "gpio109";
				drive-strength = <0x02>;
				bias-disable;
				output-low;
				phandle = <0x3c>;
			};
		};
	};

	timer {
		compatible = "arm,armv8-timer";
		interrupts = <0x01 0x02 0xff08 0x01 0x03 0xff08 0x01 0x04 0xff08 0x01 0x01 0xff08>;
		phandle = <0x9c>;
	};

	vph-pwr-regulator {
		compatible = "regulator-fixed";
		regulator-name = "vph_pwr";
		regulator-min-microvolt = <0x36ee80>;
		regulator-max-microvolt = <0x36ee80>;
		regulator-always-on;
		phandle = <0x0f>;
	};

	thermal-zones {

		pm8994-thermal {
			polling-delay-passive = <0xfa>;
			polling-delay = <0x3e8>;
			thermal-sensors = <0x49>;

			trips {

				pm8994-alert0 {
					temperature = <0x17318>;
					hysteresis = <0x7d0>;
					type = "passive";
					phandle = <0x9d>;
				};

				pm8994-crit {
					temperature = <0x1e848>;
					hysteresis = <0x7d0>;
					type = "critical";
					phandle = <0x9e>;
				};
			};
		};
	};

	gpio_keys {
		compatible = "gpio-keys";
		input-name = "gpio-keys";
		#address-cells = <0x01>;
		#size-cells = <0x00>;
		autorepeat;

		button@0 {
			label = "Volume Down";
			gpios = <0x47 0x02 0x01>;
			linux,input-type = <0x01>;
			linux,code = <0x72>;
			wakeup-source;
			debounce-interval = <0x0f>;
		};

		button@1 {
			label = "Volume Up";
			gpios = <0x47 0x03 0x01>;
			linux,input-type = <0x01>;
			linux,code = <0x73>;
			wakeup-source;
			debounce-interval = <0x0f>;
		};

		button@2 {
			label = "Camera Snapshot";
			gpios = <0x47 0x04 0x01>;
			linux,input-type = <0x01>;
			linux,code = <0xd4>;
			wakeup-source;
			debounce-interval = <0x0f>;
		};

		button@3 {
			label = "Camera Focus";
			gpios = <0x47 0x05 0x01>;
			linux,input-type = <0x01>;
			linux,code = <0x73>;
			wakeup-source;
			debounce-interval = <0x0f>;
		};
	};

	__symbols__ {
		xo_board = "/clocks/xo-board";
		sleep_clk = "/clocks/sleep-clk";
		CPU0 = "/cpus/cpu@0";
		L2_0 = "/cpus/cpu@0/l2-cache";
		CPU1 = "/cpus/cpu@1";
		CPU2 = "/cpus/cpu@2";
		CPU3 = "/cpus/cpu@3";
		CPU4 = "/cpus/cpu@100";
		L2_1 = "/cpus/cpu@100/l2-cache";
		CPU5 = "/cpus/cpu@101";
		CPU6 = "/cpus/cpu@102";
		CPU7 = "/cpus/cpu@103";
		cpu6_map = "/cpus/cpu-map/cluster1/core2";
		cpu7_map = "/cpus/cpu-map/cluster1/core3";
		tcsr_mutex = "/hwlock";
		dfps_data_mem = "/reserved-memory/dfps_data_mem@3400000";
		cont_splash_mem = "/reserved-memory/memory@3401000";
		smem_mem = "/reserved-memory/smem_region@6a00000";
		mpss_mem = "/reserved-memory/memory@7000000";
		peripheral_region = "/reserved-memory/memory@ca00000";
		rmtfs_mem = "/reserved-memory/memory@c6400000";
		mba_mem = "/reserved-memory/memory@c6700000";
		audio_mem = "/reserved-memory/memory@c7000000";
		adsp_mem = "/reserved-memory/memory@c9400000";
		fb_region = "/reserved-memory/fb_region@40000000";
		tzapp = "/reserved-memory/memory@c7800000";
		rpm_requests = "/smd/rpm/rpm-requests";
		rpmcc = "/smd/rpm/rpm-requests/rpmcc";
		rpmpd = "/smd/rpm/rpm-requests/power-controller";
		rpmpd_opp_table = "/smd/rpm/rpm-requests/power-controller/opp-table";
		rpmpd_opp_ret = "/smd/rpm/rpm-requests/power-controller/opp-table/opp1";
		rpmpd_opp_svs_krait = "/smd/rpm/rpm-requests/power-controller/opp-table/opp2";
		rpmpd_opp_svs_soc = "/smd/rpm/rpm-requests/power-controller/opp-table/opp3";
		rpmpd_opp_nom = "/smd/rpm/rpm-requests/power-controller/opp-table/opp4";
		rpmpd_opp_turbo = "/smd/rpm/rpm-requests/power-controller/opp-table/opp5";
		rpmpd_opp_super_turbo = "/smd/rpm/rpm-requests/power-controller/opp-table/opp6";
		pm8994_regulators = "/smd/rpm/rpm-requests/pm8994-regulators";
		pm8994_s3 = "/smd/rpm/rpm-requests/pm8994-regulators/s3";
		pm8994_s4 = "/smd/rpm/rpm-requests/pm8994-regulators/s4";
		pm8994_s5 = "/smd/rpm/rpm-requests/pm8994-regulators/s5";
		pm8994_s7 = "/smd/rpm/rpm-requests/pm8994-regulators/s7";
		pm8994_l1 = "/smd/rpm/rpm-requests/pm8994-regulators/l1";
		pm8994_l2 = "/smd/rpm/rpm-requests/pm8994-regulators/l2";
		pm8994_l3 = "/smd/rpm/rpm-requests/pm8994-regulators/l3";
		pm8994_l4 = "/smd/rpm/rpm-requests/pm8994-regulators/l4";
		pm8994_l6 = "/smd/rpm/rpm-requests/pm8994-regulators/l6";
		pm8994_l8 = "/smd/rpm/rpm-requests/pm8994-regulators/l8";
		pm8994_l9 = "/smd/rpm/rpm-requests/pm8994-regulators/l9";
		pm8994_l10 = "/smd/rpm/rpm-requests/pm8994-regulators/l10";
		pm8994_l11 = "/smd/rpm/rpm-requests/pm8994-regulators/l11";
		pm8994_l12 = "/smd/rpm/rpm-requests/pm8994-regulators/l12";
		pm8994_l13 = "/smd/rpm/rpm-requests/pm8994-regulators/l13";
		pm8994_l14 = "/smd/rpm/rpm-requests/pm8994-regulators/l14";
		pm8994_l15 = "/smd/rpm/rpm-requests/pm8994-regulators/l15";
		pm8994_l16 = "/smd/rpm/rpm-requests/pm8994-regulators/l16";
		pm8994_l17 = "/smd/rpm/rpm-requests/pm8994-regulators/l17";
		pm8994_l18 = "/smd/rpm/rpm-requests/pm8994-regulators/l18";
		pm8994_l19 = "/smd/rpm/rpm-requests/pm8994-regulators/l19";
		pm8994_l20 = "/smd/rpm/rpm-requests/pm8994-regulators/l20";
		pm8994_l21 = "/smd/rpm/rpm-requests/pm8994-regulators/l21";
		pm8994_l22 = "/smd/rpm/rpm-requests/pm8994-regulators/l22";
		pm8994_l23 = "/smd/rpm/rpm-requests/pm8994-regulators/l23";
		pm8994_l24 = "/smd/rpm/rpm-requests/pm8994-regulators/l24";
		pm8994_l25 = "/smd/rpm/rpm-requests/pm8994-regulators/l25";
		pm8994_l26 = "/smd/rpm/rpm-requests/pm8994-regulators/l26";
		pm8994_l27 = "/smd/rpm/rpm-requests/pm8994-regulators/l27";
		pm8994_l28 = "/smd/rpm/rpm-requests/pm8994-regulators/l28";
		pm8994_l29 = "/smd/rpm/rpm-requests/pm8994-regulators/l29";
		pm8994_l30 = "/smd/rpm/rpm-requests/pm8994-regulators/l30";
		pm8994_l31 = "/smd/rpm/rpm-requests/pm8994-regulators/l31";
		pm8994_l32 = "/smd/rpm/rpm-requests/pm8994-regulators/l32";
		pm8994_lvs1 = "/smd/rpm/rpm-requests/pm8994-regulators/lvs1";
		pm8994_lvs2 = "/smd/rpm/rpm-requests/pm8994-regulators/lvs2";
		pmi8994_regulators = "/smd/rpm/rpm-requests/pmi8994-regulators";
		pmi8994_s1 = "/smd/rpm/rpm-requests/pmi8994-regulators/s1";
		pmi8994_bby = "/smd/rpm/rpm-requests/pmi8994-regulators/boost-bypass";
		adsp_smp2p_out = "/smp2p-lpass/master-kernel";
		adsp_smp2p_in = "/smp2p-lpass/slave-kernel";
		modem_smp2p_out = "/smp2p-modem/master-kernel";
		modem_smp2p_in = "/smp2p-modem/slave-kernel";
		soc = "/soc";
		intc = "/soc/interrupt-controller@f9000000";
		apcs = "/soc/mailbox@f900d000";
		usb3 = "/soc/usb@f92f8800";
		sdhc1 = "/soc/sdhci@f9824900";
		sdhc2 = "/soc/sdhci@f98a4900";
		blsp1_dma = "/soc/dma-controller@f9904000";
		blsp1_uart2 = "/soc/serial@f991e000";
		blsp1_i2c1 = "/soc/i2c@f9923000";
		blsp1_spi1 = "/soc/spi@f9923000";
		blsp1_i2c2 = "/soc/i2c@f9924000";
		blsp1_i2c4 = "/soc/i2c@f9926000";
		blsp1_i2c5 = "/soc/i2c@f9927000";
		blsp1_i2c6 = "/soc/i2c@f9928000";
		touchscreen = "/soc/i2c@f9928000/rmi4-i2c-dev@2c";
		blsp2_dma = "/soc/dma-controller@f9944000";
		blsp2_uart2 = "/soc/serial@f995e000";
		blsp2_i2c1 = "/soc/i2c@f9963000";
		blsp2_spi4 = "/soc/spi@f9966000";
		blsp2_i2c5 = "/soc/i2c@f9967000";
		gcc = "/soc/clock-controller@fc400000";
		rpm_msg_ram = "/soc/sram@fc428000";
		spmi_bus = "/soc/spmi@fc4c0000";
		pm8994_pon = "/soc/spmi@fc4c0000/pmic@0/pon@800";
		pm8994_resin = "/soc/spmi@fc4c0000/pmic@0/pon@800/resin";
		pm8994_temp = "/soc/spmi@fc4c0000/pmic@0/temp-alarm@2400";
		pm8994_vadc = "/soc/spmi@fc4c0000/pmic@0/adc@3100";
		pm8994_gpios = "/soc/spmi@fc4c0000/pmic@0/gpios@c000";
		pm8994_mpps = "/soc/spmi@fc4c0000/pmic@0/mpps@a000";
		pm8994_spmi_regulators = "/soc/spmi@fc4c0000/pmic@1/regulators";
		pmi8994_gpios = "/soc/spmi@fc4c0000/pmic@2/gpios@c000";
		pmi8994_spmi_regulators = "/soc/spmi@fc4c0000/pmic@3/regulators";
		vdd_gfx = "/soc/spmi@fc4c0000/pmic@3/regulators/s2@1700";
		pmi8994_wled = "/soc/spmi@fc4c0000/pmic@3/wled@d800";
		tcsr_mutex_regs = "/soc/syscon@fd484000";
		tlmm = "/soc/pinctrl@fd510000";
		blsp1_uart2_default = "/soc/pinctrl@fd510000/blsp1-uart2-default";
		blsp1_uart2_sleep = "/soc/pinctrl@fd510000/blsp1-uart2-sleep";
		blsp2_uart2_default = "/soc/pinctrl@fd510000/blsp2-uart2-default";
		blsp2_uart2_sleep = "/soc/pinctrl@fd510000/blsp2-uart2-sleep";
		i2c1_default = "/soc/pinctrl@fd510000/i2c1-default";
		i2c1_sleep = "/soc/pinctrl@fd510000/i2c1-sleep";
		i2c2_default = "/soc/pinctrl@fd510000/i2c2-default";
		i2c2_sleep = "/soc/pinctrl@fd510000/i2c2-sleep";
		i2c4_default = "/soc/pinctrl@fd510000/i2c4-default";
		i2c4_sleep = "/soc/pinctrl@fd510000/i2c4-sleep";
		i2c5_default = "/soc/pinctrl@fd510000/i2c5-default";
		i2c5_sleep = "/soc/pinctrl@fd510000/i2c5-sleep";
		i2c6_default = "/soc/pinctrl@fd510000/i2c6-default";
		i2c6_sleep = "/soc/pinctrl@fd510000/i2c6-sleep";
		i2c7_default = "/soc/pinctrl@fd510000/i2c7-default";
		i2c7_sleep = "/soc/pinctrl@fd510000/i2c7-sleep";
		blsp2_spi10_default = "/soc/pinctrl@fd510000/blsp2-spi10-default";
		blsp2_spi10_sleep = "/soc/pinctrl@fd510000/blsp2-spi10-sleep";
		i2c11_default = "/soc/pinctrl@fd510000/i2c11-default";
		i2c11_sleep = "/soc/pinctrl@fd510000/i2c11-sleep";
		blsp1_spi1_default = "/soc/pinctrl@fd510000/blsp1-spi1-default";
		blsp1_spi1_sleep = "/soc/pinctrl@fd510000/blsp1-spi1-sleep";
		sdc1_clk_on = "/soc/pinctrl@fd510000/clk-on";
		sdc1_clk_off = "/soc/pinctrl@fd510000/clk-off";
		sdc1_cmd_on = "/soc/pinctrl@fd510000/cmd-on";
		sdc1_cmd_off = "/soc/pinctrl@fd510000/cmd-off";
		sdc1_data_on = "/soc/pinctrl@fd510000/data-on";
		sdc1_data_off = "/soc/pinctrl@fd510000/data-off";
		sdc1_rclk_on = "/soc/pinctrl@fd510000/rclk-on";
		sdc1_rclk_off = "/soc/pinctrl@fd510000/rclk-off";
		sdc2_clk_on = "/soc/pinctrl@fd510000/sdc2-clk-on";
		sdc2_clk_off = "/soc/pinctrl@fd510000/sdc2-clk-off";
		sdc2_cmd_on = "/soc/pinctrl@fd510000/sdc2-cmd-on";
		sdc2_cmd_off = "/soc/pinctrl@fd510000/sdc2-cmd-off";
		sdc2_data_on = "/soc/pinctrl@fd510000/sdc2-data-on";
		sdc2_data_off = "/soc/pinctrl@fd510000/sdc2-data-off";
		ts_int_active = "/soc/pinctrl@fd510000/ts-int-active";
		ts_reset_active = "/soc/pinctrl@fd510000/ts-reset-active";
		timer = "/timer";
		vph_pwr = "/vph-pwr-regulator";
		pm8994_alert0 = "/thermal-zones/pm8994-thermal/trips/pm8994-alert0";
		pm8994_crit = "/thermal-zones/pm8994-thermal/trips/pm8994-crit";
	};
};
